AUTOSAR XML (schema 4-0-3)
standard types defined: Boolean, UInt32
package /AUTOSAR_Platform/DataConstrs
  range DC_Boolean: raw 0..1
package /PATAC/MSM/ComponentTypes
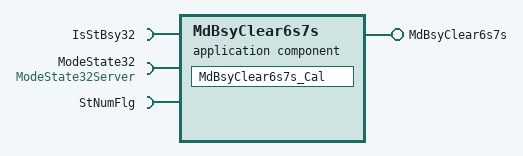
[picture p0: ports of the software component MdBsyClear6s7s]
  application sw component type MdBsyClear6s7s
    provide port MdBsyClear6s7s: server-com-spec{operation=Cal, queue-length=1}, provided-interface=MdBsyClear6s7s
    require port IsStBsy32: required-com-specs=[IsStBsy32/Clear, IsStBsy32/Get, IsStBsy32/Set], required-interface=IsStBsy32
    require port ModeState32: required-com-specs=[ModeState32Server/Clear, ModeState32Server/Get, ModeState32Server/Set], required-interface=ModeState32Server
    require port StNumFlg: required-interface=StNumFlg
      required-com-specs:
        data-element=Is4s, filter=data-filter-type=ALWAYS, init-value=0
        data-element=Is6s, filter=data-filter-type=ALWAYS, init-value=0
        data-element=Is6s7s, filter=data-filter-type=ALWAYS, init-value=0
        data-element=Is7s, filter=data-filter-type=ALWAYS, init-value=0
    behavior MdBsyClear6s7s_InternalBehavior
      operation invoked event OIT_MdBsyClear6s7s_Cal_MdBsyClear6s7s_Cal: start-on-event=MdBsyClear6s7s_Cal, operation=MdBsyClear6s7s.Cal
      runnable MdBsyClear6s7s_Cal
        data-receive-point-by-arguments:
          access REC_StNumFlg_Is6s: accessed-variable=StNumFlg.Is6s
          access REC_StNumFlg_Is7s: accessed-variable=StNumFlg.Is7s
        sync call SC_IsStBsy32_Clear: operation=IsStBsy32.Clear, timeout=0
        sync call SC_ModeState32_Get: operation=ModeState32.Get, timeout=0
  swc implementation MdBsyClear6s7s_Implementation: behavior=MdBsyClear6s7s_InternalBehavior
    code-descriptors:
      code Default: artifact-descriptors=autosar-engineering-object={short-label=Default, category=SWSRC}
package /PATAC/MSM/ModeAdjust/PortInterface
  client server interface IsStBsy32
    operation Clear
      arg ClearBit: type=UInt32, direction=IN, server-argument-impl-policy=USE-ARGUMENT-TYPE
    operation Get
      arg IsStBsy32Bit: type=UInt32, direction=OUT, server-argument-impl-policy=USE-ARGUMENT-TYPE
    operation Set
      arg SetBit: type=UInt32, direction=IN, server-argument-impl-policy=USE-ARGUMENT-TYPE
  client server interface MdBsyClear6s7s
    operation Cal
  client server interface ModeState32Server
    operation Clear
      arg ClearBit: type=UInt32, direction=IN, server-argument-impl-policy=USE-ARGUMENT-TYPE
    operation Get
      arg MdEn32: type=UInt32, direction=OUT, server-argument-impl-policy=USE-ARGUMENT-TYPE
    operation Set
      arg SetBit: type=UInt32, direction=IN, server-argument-impl-policy=USE-ARGUMENT-TYPE
  sender receiver interface StNumFlg
    4 x data, all with type=Boolean:
      Is4s
      Is6s
      Is6s7s
      Is7s
    invalidation-policys:
      data-element=Is7s, handle-invalid=DONT-INVALIDATE
      data-element=Is6s, handle-invalid=DONT-INVALIDATE
      data-element=Is4s, handle-invalid=DONT-INVALIDATE
      data-element=Is6s7s, handle-invalid=DONT-INVALIDATE
